VERSION ""

NS_ :

BS_:

BU_: XXX

BO_ 380 Car_Motion: 8 XXX
 SG_ Gas_Pressed_probably : 39|1@0+ (1,0) [0|1] "" XXX
 SG_ RPM_probably : 23|16@0+ (1,0) [0|65535] "rpm" XXX

BO_ 356 NEW_MSG_1: 8 XXX

BO_ 432 NEW_MSG_2: 8 XXX

BO_ 476 NEW_MSG_3: 8 XXX

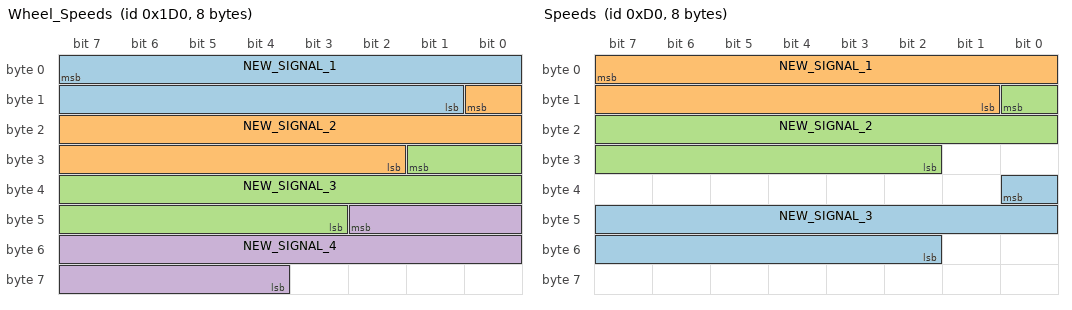
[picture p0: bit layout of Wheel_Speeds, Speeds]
BO_ 464 Wheel_Speeds: 8 XXX
 SG_ NEW_SIGNAL_1 : 7|15@0+ (1,0) [0|32767] "" XXX
 SG_ NEW_SIGNAL_2 : 8|15@0+ (1,0) [0|65535] "" XXX
 SG_ NEW_SIGNAL_3 : 25|15@0+ (1,0) [0|1023] "" XXX
 SG_ NEW_SIGNAL_4 : 42|15@0+ (1,0) [0|7] "" XXX

BO_ 344 Car_Motion2: 8 XXX
 SG_ Brake_pressed_possibly : 33|1@0+ (1,0) [0|1] "" XXX
 SG_ Speed_probably : 7|16@0+ (1,0) [0|65535] "" XXX
 SG_ Speed2_probably : 39|16@0+ (1,0) [0|65535] "" XXX
 SG_ Trip_Meter_probably : 55|8@0+ (1,0) [0|255] "" XXX

BO_ 319 NEW_MSG_5: 8 XXX

BO_ 660 NEW_MSG_6: 8 XXX

BO_ 420 NEW_MSG_7: 8 XXX

BO_ 310 Test_Later: 8 XXX
 SG_ Test_later : 31|16@0- (1,0) [-32000|32000] "" XXX

BO_ 398 Nearest_to_Steering: 8 XXX
 SG_ Some_relation_to_steering : 15|16@0+ (1,0) [-31000|31000] "" XXX

BO_ 208 Speeds: 8 XXX
 SG_ NEW_SIGNAL_3 : 32|15@0+ (1,0) [0|511] "" XXX
 SG_ NEW_SIGNAL_1 : 7|15@0+ (1,0) [0|65535] "" XXX
 SG_ NEW_SIGNAL_2 : 8|15@0+ (1,0) [0|65535] "" XXX

BO_ 314 GAS: 8 XXX
 SG_ Gas_Pedal : 15|8@0+ (1,0) [0|1] "" XXX

BO_ 804 NEW_MSG_4: 8 XXX
